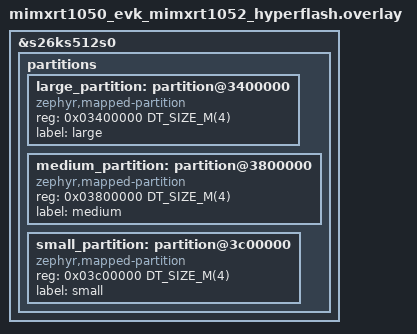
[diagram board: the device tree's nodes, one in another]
/*
 * Copyright 2025 NXP
 *
 * SPDX-License-Identifier: Apache-2.0
 */

/delete-node/ &storage_partition;

&s26ks512s0 {
	partitions {
		large_partition: partition@3400000 {
			compatible = "zephyr,mapped-partition";
			reg = <0x03400000 DT_SIZE_M(4)>;
			label = "large";
		};

		medium_partition: partition@3800000 {
			compatible = "zephyr,mapped-partition";
			reg = <0x03800000 DT_SIZE_M(4)>;
			label = "medium";
		};

		small_partition: partition@3c00000 {
			compatible = "zephyr,mapped-partition";
			reg = <0x03c00000 DT_SIZE_M(4)>;
			label = "small";
		};
	};
};
